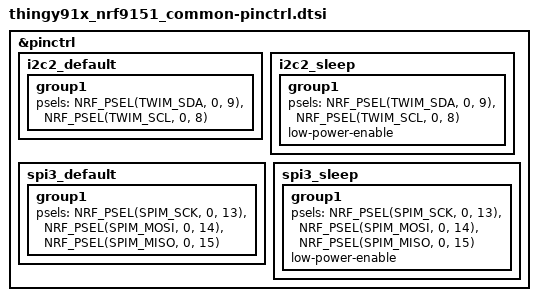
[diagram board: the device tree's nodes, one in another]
/*
 * Copyright (c) 2025 Embeint Holdings Pty Ltd
 * SPDX-License-Identifier: Apache-2.0
 */

&pinctrl {
	i2c2_default: i2c2_default {
		group1 {
			psels = <NRF_PSEL(TWIM_SDA, 0, 9)>,
				<NRF_PSEL(TWIM_SCL, 0, 8)>;
		};
	};

	i2c2_sleep: i2c2_sleep {
		group1 {
			psels = <NRF_PSEL(TWIM_SDA, 0, 9)>,
				<NRF_PSEL(TWIM_SCL, 0, 8)>;
			low-power-enable;
		};
	};

	spi3_default: spi3_default {
		group1 {
			psels = <NRF_PSEL(SPIM_SCK, 0, 13)>,
				<NRF_PSEL(SPIM_MOSI, 0, 14)>,
				<NRF_PSEL(SPIM_MISO, 0, 15)>;
		};
	};

	spi3_sleep: spi3_sleep {
		group1 {
			psels = <NRF_PSEL(SPIM_SCK, 0, 13)>,
				<NRF_PSEL(SPIM_MOSI, 0, 14)>,
				<NRF_PSEL(SPIM_MISO, 0, 15)>;
			low-power-enable;
		};
	};
};
